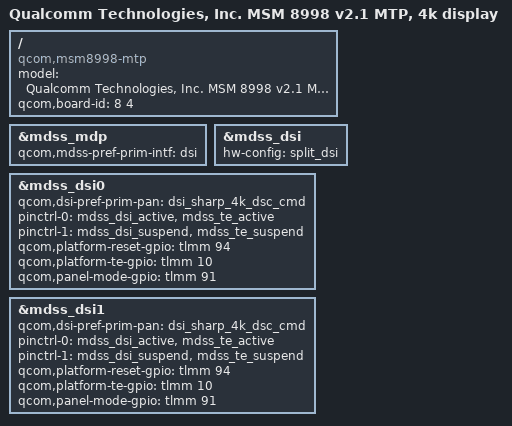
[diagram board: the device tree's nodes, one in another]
/* Copyright (c) 2017, The Linux Foundation. All rights reserved.
 *
 * This program is free software; you can redistribute it and/or modify
 * it under the terms of the GNU General Public License version 2 and
 * only version 2 as published by the Free Software Foundation.
 *
 * This program is distributed in the hope that it will be useful,
 * but WITHOUT ANY WARRANTY; without even the implied warranty of
 * MERCHANTABILITY or FITNESS FOR A PARTICULAR PURPOSE.  See the
 * GNU General Public License for more details.
 */


/dts-v1/;

#include "msm8998-v2.1.dtsi"
#include "msm8998-mdss-panels.dtsi"
#include "msm8998-mtp.dtsi"

/ {
	model = "Qualcomm Technologies, Inc. MSM 8998 v2.1 MTP, 4k display";
	compatible = "qcom,msm8998-mtp", "qcom,msm8998", "qcom,mtp";
	qcom,board-id = <8 4>;
};

&mdss_mdp {
	qcom,mdss-pref-prim-intf = "dsi";
};

&mdss_dsi {
	hw-config = "split_dsi";
};

&mdss_dsi0 {
	qcom,dsi-pref-prim-pan = <&dsi_sharp_4k_dsc_cmd>;
	pinctrl-names = "mdss_default", "mdss_sleep";
	pinctrl-0 = <&mdss_dsi_active &mdss_te_active>;
	pinctrl-1 = <&mdss_dsi_suspend &mdss_te_suspend>;
	qcom,platform-reset-gpio = <&tlmm 94 0>;
	qcom,platform-te-gpio = <&tlmm 10 0>;
	qcom,panel-mode-gpio = <&tlmm 91 0>;
};

&mdss_dsi1 {
	qcom,dsi-pref-prim-pan = <&dsi_sharp_4k_dsc_cmd>;
	pinctrl-names = "mdss_default", "mdss_sleep";
	pinctrl-0 = <&mdss_dsi_active &mdss_te_active>;
	pinctrl-1 = <&mdss_dsi_suspend &mdss_te_suspend>;
	qcom,platform-reset-gpio = <&tlmm 94 0>;
	qcom,platform-te-gpio = <&tlmm 10 0>;
	qcom,panel-mode-gpio = <&tlmm 91 0>;
};
